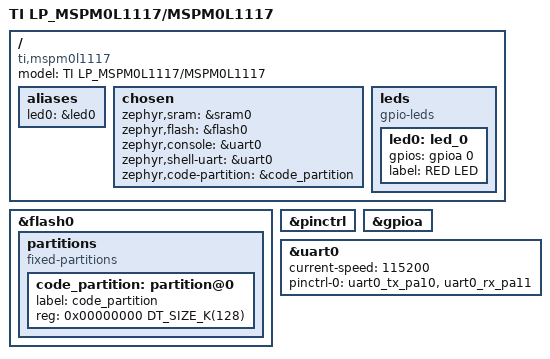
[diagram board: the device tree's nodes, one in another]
/*
 * Copyright (c) 2025 Texas Instruments
 * Copyright (c) 2025 Linumiz GmbH
 *
 * SPDX-License-Identifier: Apache-2.0
 */

/dts-v1/;

#include <ti/mspm0/l/mspm0l1117.dtsi>
#include <ti/mspm0/l/mspm0l111x-pinctrl.dtsi>
#include <zephyr/dt-bindings/clock/mspm0_clock.h>
#include <zephyr/dt-bindings/gpio/gpio.h>

/ {
	model = "TI LP_MSPM0L1117/MSPM0L1117";
	compatible = "ti,mspm0l1117";

	aliases {
		led0 = &led0;
	};

	chosen {
		zephyr,sram = &sram0;
		zephyr,flash = &flash0;
		zephyr,console = &uart0;
		zephyr,shell-uart = &uart0;
		zephyr,code-partition = &code_partition;
	};

	leds {
		compatible = "gpio-leds";

		led0: led_0 {
			gpios = <&gpioa 0 GPIO_ACTIVE_HIGH>;
			label = "RED LED";
		};
	};
};

&flash0 {
	status = "okay";

	partitions {
		compatible = "fixed-partitions";
		#address-cells = <1>;
		#size-cells = <1>;

		code_partition: partition@0 {
			label = "code_partition";
			reg = <0x00000000 DT_SIZE_K(128)>;
		};
	};
};

&pinctrl {
	status = "okay";
};

&gpioa {
	status = "okay";
};

&uart0 {
	status = "okay";
	current-speed = <115200>;
	pinctrl-0 = <&uart0_tx_pa10 &uart0_rx_pa11>;
	pinctrl-names = "default";
};
